VERSION "DNNBNNNYNNNNNNNNNNNNNNNNNNYYYNNNNNNNNNNNNN/4/%%%/4/'%**4NNN///"

NS_ :

BS_:

BU_: Chassis

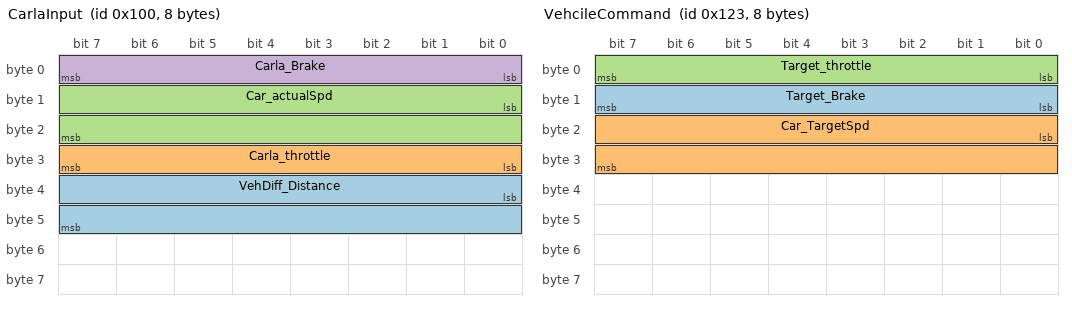
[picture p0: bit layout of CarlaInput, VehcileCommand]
BO_ 256 CarlaInput: 8 Chassis
 SG_ VehDiff_Distance : 32|16@1+ (0.01,0) [0|600] "m" Vector__XXX
 SG_ Carla_throttle : 24|8@1+ (0.005,0) [0|1] "" Vector__XXX
 SG_ Car_actualSpd : 8|16@1+ (0.1,0) [0|6553.5] "km/h" Vector__XXX
 SG_ Carla_Brake : 0|8@1+ (0.005,0) [0|1.275] "" Vector__XXX

BO_ 291 VehcileCommand: 8 Chassis
 SG_ Target_Brake : 8|8@1+ (0.005,0) [0|1] "" Vector__XXX
 SG_ Car_TargetSpd : 16|16@1+ (0.1,0) [0|655] "km/h" Vector__XXX
 SG_ Target_throttle : 0|8@1+ (0.005,0) [0|1] ""  Chassis

BA_DEF_ BU_  "ILUsed" ENUM  "Yes","No";
BA_DEF_ SG_  "GenSigStartValue" FLOAT 0 1215752192;
BA_DEF_ SG_  "GenSigSendType" ENUM  "Cyclic","OnWrite","OnWriteWithRepetition","OnChange","OnChangeWithRepetition","IfActive","IfActiveWithRepetition";
BA_DEF_ BO_  "GenMsgDelayTime" INT 1 1000;
BA_DEF_ BO_  "GenMsgCycleTime" INT 2 50000;
BA_DEF_ BO_  "GenMsgSendType" ENUM  "Cyclic","not_used","not_used","not_used","not_used","Cyclic","not_used","IfActive";
BA_DEF_ BO_  "GenMsgCycleTimeFast" INT 2 100000;
BA_DEF_ BO_  "GenMsgILSupport" ENUM  "No","Yes";
BA_DEF_ BU_  "NodeLayerModules" STRING ;
BA_DEF_  "GenEnvVarPrefix" STRING ;
BA_DEF_  "GenEnvVarEndingSnd" STRING ;
BA_DEF_  "GenEnvVarEndingDsp" STRING ;
BA_DEF_DEF_  "ILUsed" "Yes";
BA_DEF_DEF_  "GenSigStartValue" 0;
BA_DEF_DEF_  "GenSigSendType" "Cyclic";
BA_DEF_DEF_  "GenMsgDelayTime" 1;
BA_DEF_DEF_  "GenMsgCycleTime" 2;
BA_DEF_DEF_  "GenMsgSendType" "not_used";
BA_DEF_DEF_  "GenMsgCycleTimeFast" 100;
BA_DEF_DEF_  "GenMsgILSupport" "Yes";
BA_DEF_DEF_  "NodeLayerModules" "CANoeILNLVector.dll";
BA_DEF_DEF_  "GenEnvVarPrefix" "Env";
BA_DEF_DEF_  "GenEnvVarEndingSnd" "_";
BA_DEF_DEF_  "GenEnvVarEndingDsp" "Dsp_";
BA_ "GenMsgCycleTime" BO_ 256 50;
BA_ "GenMsgSendType" BO_ 256 0;
BA_ "GenMsgSendType" BO_ 291 0;
BA_ "GenMsgCycleTime" BO_ 291 50;
